# KM1M7CF14 register map
Vendor: Nuvoton Technology Corporation Japan; Series: KM1M7CF; File version: 1.0.3
CPU: CM7 r1p2, little endian, MPU, FPU, double-precision FPU, I-cache, D-cache, ITCM, DTCM, 4 interrupt priority bits
Registers are 32-bit, read-write, no defined reset value unless marked. A register's access mark holds for its fields unless they carry their own. Offsets are from the block's base; [hi:lo] are bit positions.

## RTC — Real time clock
Base 0x40052000
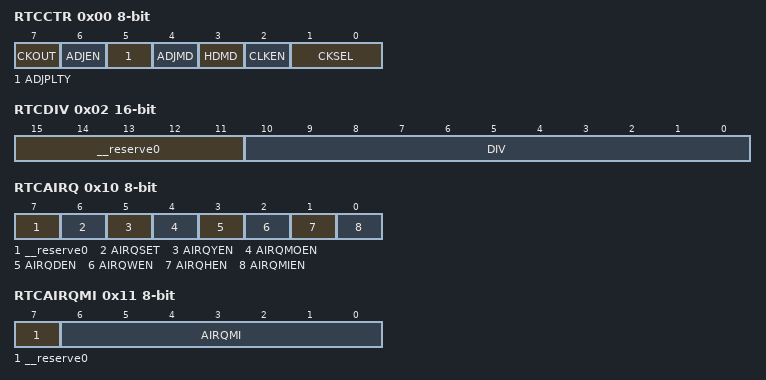
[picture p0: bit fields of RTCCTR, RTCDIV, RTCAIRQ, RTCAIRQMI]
0x00 RTCCTR 8-bit — Real Time Clock Control Register
  [7] CKOUT — 1 Hz clock pin output
  [6] ADJEN — Clock adjustment
  [5] ADJPLTY — Clock correction value
  [4] ADJMD — Clock adjustment
  [3] HDMD — Display mode
  [2] CLKEN — RTC operation
  [1:0] CKSEL — Select a clock source.
0x02 RTCDIV 16-bit access per field — Clock Source-Dividing Setting Register
  [15:11] __reserve0 ro — "0" is always read out.
  [10:0] DIV rw — Real Time Clock operates with the base clock (16,384 Hz) that is generated by dividing a clock source.
0x10 RTCAIRQ 8-bit access per field — Alarm Interrupt Control Register
  [7] __reserve0 ro — "0" is always read out.
  [6] AIRQSET rw — Alarm interrupt control register setting
  [5] AIRQYEN rw — Compares alarm time (year).
  [4] AIRQMOEN rw — Compares alarm time (month).
  [3] AIRQDEN rw — Compares alarm time (date of the month)
  [2] AIRQWEN rw — Compares alarm time (day of the week).
  [1] AIRQHEN rw — Compares alarm time (hour).
  [0] AIRQMIEN rw — Compares alarm time (minute).
0x11 RTCAIRQMI 8-bit access per field — Alarm Time Setting Register (Minute)
  [7] __reserve0 ro — "0" is always read out.
  [6:0] AIRQMI rw — Set a value within a range of "00" to "59" using the BCD format.
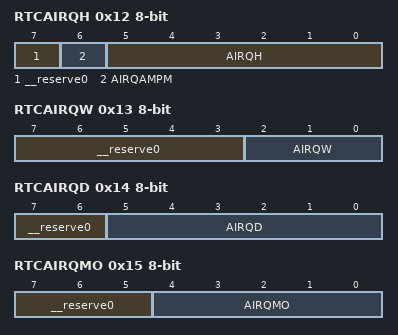
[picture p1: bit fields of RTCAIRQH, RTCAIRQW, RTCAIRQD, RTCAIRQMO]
0x12 RTCAIRQH 8-bit access per field — Alarm Time Setting Register (Hour)
  [7] __reserve0 ro — "0" is always read out.
  [6] AIRQAMPM rw — 0: a.m.
  [5:0] AIRQH rw — (1) In 24-hour display mode: Set a value within a range of "00" to "23" using the BCD format.
0x13 RTCAIRQW 8-bit access per field — Alarm Time Setting Register (Day of the Week)
  [7:3] __reserve0 ro — "0" is always read out.
  [2:0] AIRQW rw — Set a value within a range of "0" to "6” using the BCD format.
0x14 RTCAIRQD 8-bit access per field — Alarm Time Setting Register (Date of the Month)
  [7:6] __reserve0 ro — "0" is always read out.
  [5:0] AIRQD rw — Set a value within a range of "01" to "30","31","28" or "29" using the BCD format. (See Note 2.)
0x15 RTCAIRQMO 8-bit access per field — Alarm Time Setting Register (Month)
  [7:5] __reserve0 ro — "0" is always read out.
  [4:0] AIRQMO rw — Set a value within a range of "01" to "12" using the BCD format.
0x16 RTCAIRQY 8-bit — Alarm Time Setting Register (Year)
  [7:0] AIRQY — Set a value within a range of "00" to "99" using the BCD format.
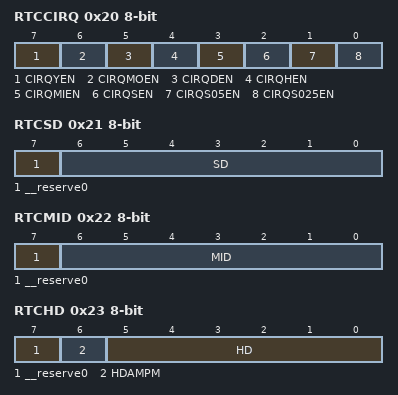
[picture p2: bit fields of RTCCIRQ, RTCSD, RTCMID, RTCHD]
0x20 RTCCIRQ 8-bit — Cycle Interrupt Control Register
  [7] CIRQYEN — Generates an interrupt every one year.
  [6] CIRQMOEN — Generates an interrupt every one month.
  [5] CIRQDEN — Generates an interrupt every one day.
  [4] CIRQHEN — Generates an interrupt every one hour.
  [3] CIRQMIEN — Generates an interrupt every one minute.
  [2] CIRQSEN — Generates an interrupt every one second.
  [1] CIRQS05EN — Generates an interrupt every 1/2 second.
  [0] CIRQS025EN — Generates an interrupt every 1/4 second.
0x21 RTCSD 8-bit access per field — Clock Register (Second)
  [7] __reserve0 ro — "0" is always read out.
  [6:0] SD rw — Counts seconds from "00" to "59" using the BCD format.
0x22 RTCMID 8-bit access per field — Clock Register (Minute)
  [7] __reserve0 ro — "0" is always read out.
  [6:0] MID rw — Counts minutes from "00" to "59" with the BCD format.
0x23 RTCHD 8-bit access per field — Clock Register (Hour)
  [7] __reserve0 ro — "0" is always read out.
  [6] HDAMPM rw — 0: a.m.
  [5:0] HD rw — (1) In 24-hour display mode: Counts hours from "00" to "23" with the BCD format. In writing data, set a value within a range of "00" to "23" using the BCD format.
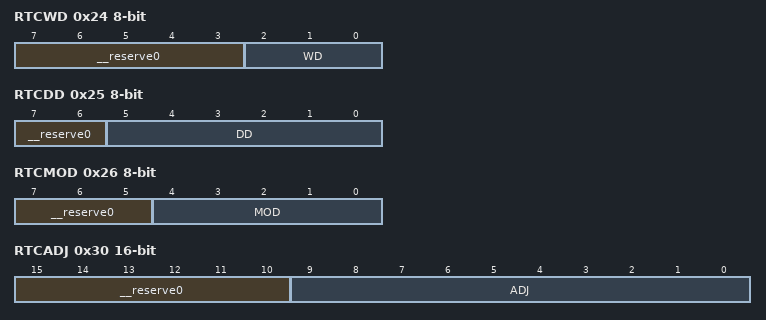
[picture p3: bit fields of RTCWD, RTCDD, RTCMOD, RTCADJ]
0x24 RTCWD 8-bit access per field — Clock Register (Day of the Week)
  [7:3] __reserve0 ro — "0" is always read out.
  [2:0] WD rw — Counts date of the week from "0" to "6" with the BCD format.
0x25 RTCDD 8-bit access per field — Clock Register (Date of the Month)
  [7:6] __reserve0 ro — "0" is always read out.
  [5:0] DD rw — Counts days from "01" to "30","31", "28" or "29" with the BCD format (See Note 2).
0x26 RTCMOD 8-bit access per field — Clock Register (Month)
  [7:5] __reserve0 ro — "0" is always read out.
  [4:0] MOD rw — Counts months from "01" to "12" with the BCD format.
0x27 RTCYD 8-bit — Clock Register (Year)
  [7:0] YD — Counts years from "00" to "99" with the BCD format.
0x30 RTCADJ 16-bit access per field — Clock Adjustment Register
  [15:10] __reserve0 ro — "0" is always read out.
  [9:0] ADJ rw — Set a value within a range of "0x000" to "0x3FF" to adjust the clock.
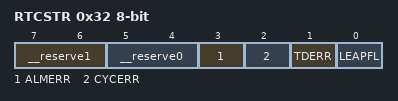
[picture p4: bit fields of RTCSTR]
0x32 RTCSTR 8-bit ro — Status Register
  [7:6] __reserve1 — "0" is always read out.
  [5:4] __reserve0
  [3] ALMERR — Alarm interrupt register setting
  [2] CYCERR — Cycle interrupt register setting
  [1] TDERR — Clock register setting
  [0] LEAPFL — Year classification
